AUTOSAR XML (schema 4-0-3)
standard types defined: Boolean, UInt32, UInt8
package /AUTOSAR_Platform/DataConstrs
  range DC_Boolean: raw 0..1
  range DC_UInt8: raw 0..255
package /PATAC/MSM/ComponentTypes
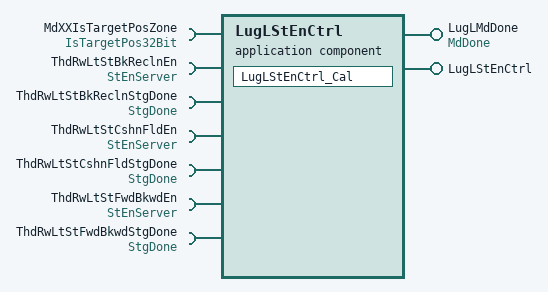
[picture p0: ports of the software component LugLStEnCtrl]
  application sw component type LugLStEnCtrl
    provide port LugLMdDone: nonqueued-sender-com-spec{data-element=MdDone/Val, init-value=0}, provided-interface=MdDone
    provide port LugLStEnCtrl: server-com-spec{operation=Cal, queue-length=1}, provided-interface=LugLStEnCtrl
    7 x require port:
      MdXXIsTargetPosZone: nonqueued-receiver-com-spec{data-element=IsTargetPos32Bit/Val, filter=data-filter-type=ALWAYS, init-value=0}, required-interface=IsTargetPos32Bit
      ThdRwLtStBkReclnEn: required-com-specs=[Clear, Get, Set], required-interface=StEnServer
      ThdRwLtStBkReclnStgDone: nonqueued-receiver-com-spec{data-element=StgDone/Val, filter=data-filter-type=ALWAYS, init-value=0}, required-interface=StgDone
      ThdRwLtStCshnFldEn: required-com-specs=[Clear, Get, Set], required-interface=StEnServer
      ThdRwLtStCshnFldStgDone: nonqueued-receiver-com-spec{data-element=StgDone/Val, filter=data-filter-type=ALWAYS, init-value=0}, required-interface=StgDone
      ThdRwLtStFwdBkwdEn: required-com-specs=[Clear, Get, Set], required-interface=StEnServer
      ThdRwLtStFwdBkwdStgDone: nonqueued-receiver-com-spec{data-element=StgDone/Val, filter=data-filter-type=ALWAYS, init-value=0}, required-interface=StgDone
    behavior LugLStEnCtrl_InternalBehavior
      operation invoked event OIT_LugLStEnCtrl_Cal_LugLStEnCtrl_Cal: start-on-event=LugLStEnCtrl_Cal, operation=LugLStEnCtrl.Cal
      runnable LugLStEnCtrl_Cal
        data-receive-point-by-arguments:
          4 x access:
            REC_MdXXIsTargetPosZone_Val: accessed-variable=MdXXIsTargetPosZone.Val
            REC_ThdRwLtStBkReclnStgDone_Val: accessed-variable=ThdRwLtStBkReclnStgDone.Val
            REC_ThdRwLtStCshnFldStgDone_Val: accessed-variable=ThdRwLtStCshnFldStgDone.Val
            REC_ThdRwLtStFwdBkwdStgDone_Val: accessed-variable=ThdRwLtStFwdBkwdStgDone.Val
        data-send-points:
          access SEND_LugLMdDone_Val: accessed-variable=LugLMdDone.Val
        6 x sync call, all with timeout=0:
          SC_ThdRwLtStBkReclnEn_Clear: operation=ThdRwLtStBkReclnEn.Clear
          SC_ThdRwLtStBkReclnEn_Set: operation=ThdRwLtStBkReclnEn.Set
          SC_ThdRwLtStCshnFldEn_Clear: operation=ThdRwLtStCshnFldEn.Clear
          SC_ThdRwLtStCshnFldEn_Set: operation=ThdRwLtStCshnFldEn.Set
          SC_ThdRwLtStFwdBkwdEn_Clear: operation=ThdRwLtStFwdBkwdEn.Clear
          SC_ThdRwLtStFwdBkwdEn_Set: operation=ThdRwLtStFwdBkwdEn.Set
  swc implementation LugLStEnCtrl_Implementation: behavior=LugLStEnCtrl_InternalBehavior
    code-descriptors:
      code Default: artifact-descriptors=autosar-engineering-object={short-label=Default, category=SWSRC}
package /PATAC/MSM/ModeAdjust/PortInterface
  client server interface LugLStEnCtrl
    operation Cal
  client server interface StEnServer
    operation Clear
      arg data: type=UInt8, direction=IN, server-argument-impl-policy=USE-ARGUMENT-TYPE
    operation Get
      arg data: type=UInt32, direction=OUT, server-argument-impl-policy=USE-ARGUMENT-TYPE
    operation Set
      arg data: type=UInt8, direction=IN, server-argument-impl-policy=USE-ARGUMENT-TYPE
  sender receiver interface IsTargetPos32Bit: invalidation-policy{data-element=IsTargetPos32Bit/Val, handle-invalid=DONT-INVALIDATE}
    data Val: type=UInt32
  sender receiver interface MdDone: invalidation-policy{data-element=MdDone/Val, handle-invalid=DONT-INVALIDATE}
    data Val: type=UInt8
  sender receiver interface StgDone: invalidation-policy{data-element=StgDone/Val, handle-invalid=DONT-INVALIDATE}
    data Val: type=Boolean
